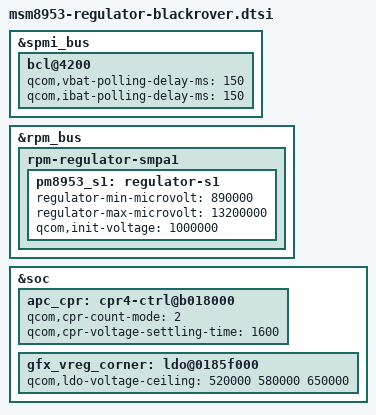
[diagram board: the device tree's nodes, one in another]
/* Copyright (c) 2018, The Linux Foundation. All rights reserved.
 * Copyright (c) 2018, Raphielscape LLC.
 *
 * SPDX-License-Identifier: GPL-2.0-or-later
 */

 #include <dt-bindings/interrupt-controller/arm-gic.h>

 &spmi_bus {
     bcl@4200 {
        /*
         * Put more saner vbat and ibat pooling delays
         * we don't need 100ms delay for vbat and ibat
         */
        qcom,vbat-polling-delay-ms = <150>;
        qcom,ibat-polling-delay-ms = <150>;
    };
 };

 &rpm_bus {
	rpm-regulator-smpa1 {
		status = "okay";
		pm8953_s1: regulator-s1 {
			regulator-min-microvolt = <890000>;
			regulator-max-microvolt = <13200000>;
			qcom,init-voltage = <1000000>;
			status = "okay";
		};
	};
 };

 &soc {
     apc_cpr: cpr4-ctrl@b018000 {
        qcom,cpr-count-mode = <2>;		/* Staggered */
        qcom,cpr-voltage-settling-time = <1600>;
     };

     gfx_vreg_corner: ldo@0185f000 {
        qcom,ldo-voltage-ceiling = <520000 580000 650000>;
     };
 };
